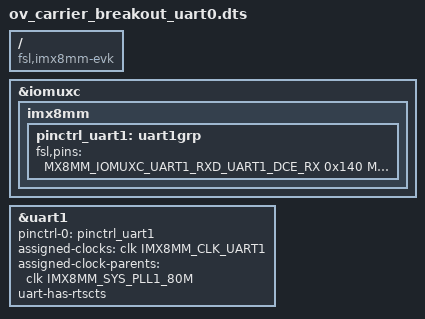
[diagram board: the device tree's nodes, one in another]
/**
 * Portenta-M8 dtb overlay file
 * Arduino 2021
 * Enable UART0 on Arduino Breakout carrier board
 * with RTS and CTS
 */

/dts-v1/;
/plugin/;

#include <dt-bindings/clock/imx8mm-clock.h>
#include "imx8mm-pinfunc.h"

/ {
	compatible = "fsl,imx8mm-evk", "fsl,imx8mm";

	fragment@0 {
		target = <&iomuxc>;
		__overlay__ {
			imx8mm {
				pinctrl_uart1: uart1grp {
					fsl,pins = <
						MX8MM_IOMUXC_UART1_RXD_UART1_DCE_RX       0x140
						MX8MM_IOMUXC_UART1_TXD_UART1_DCE_TX       0x140
						MX8MM_IOMUXC_UART3_RXD_UART1_DCE_CTS_B    0x140
						MX8MM_IOMUXC_UART3_TXD_UART1_DCE_RTS_B    0x140
					>;
				};
			};
		};
	};

	fragment@1 {
		target = <&uart1>;
		__overlay__ {
			pinctrl-names = "default";
			pinctrl-0 = <&pinctrl_uart1>;
			assigned-clocks = <&clk IMX8MM_CLK_UART1>;
			assigned-clock-parents = <&clk IMX8MM_SYS_PLL1_80M>;
			uart-has-rtscts;
			status = "okay";
		};
	};
};
